AUTOSAR XML (schema 4-2-2)
package /STELLANTIS/EPT/ASWCs
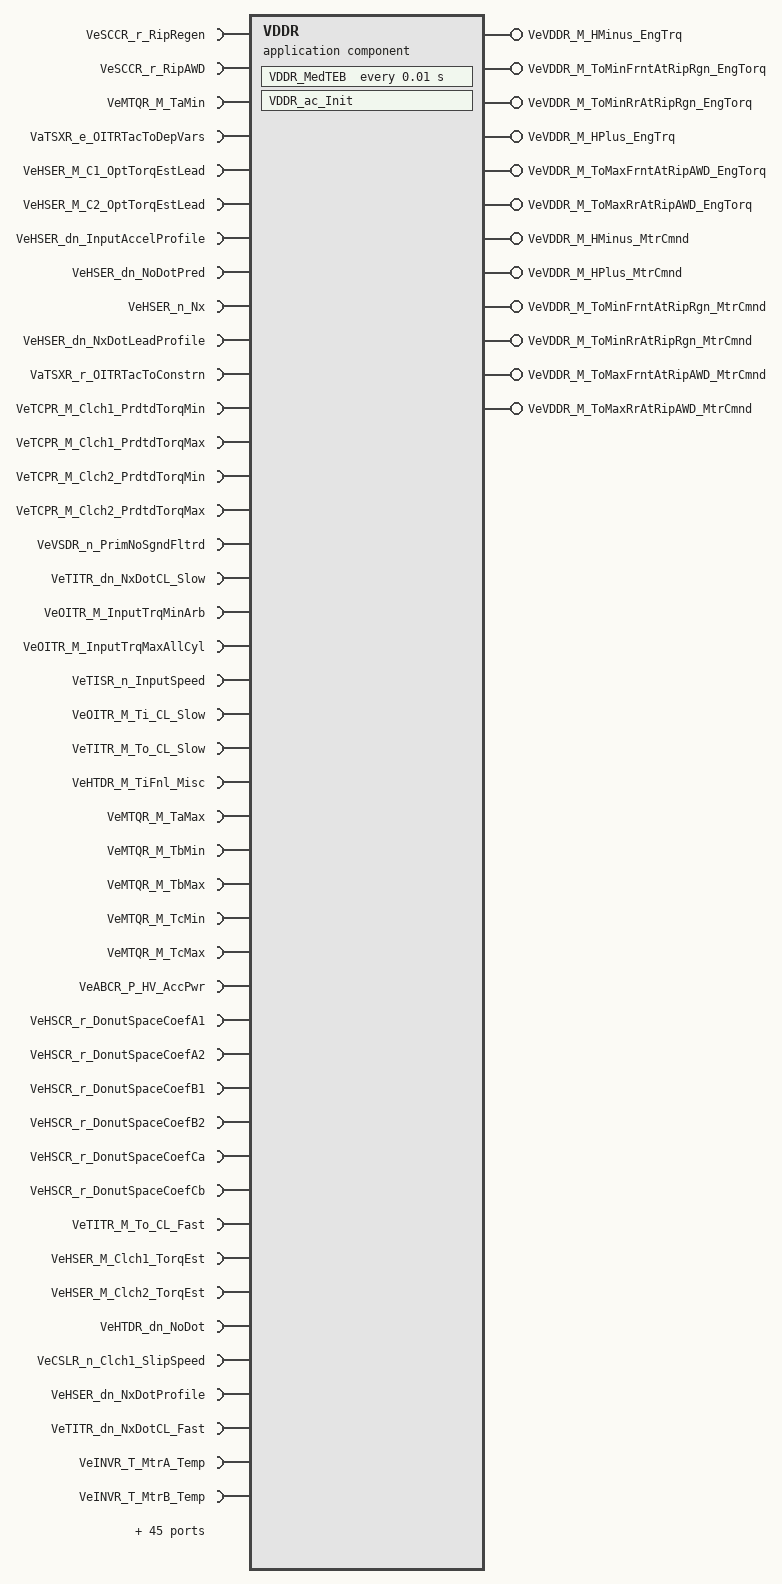
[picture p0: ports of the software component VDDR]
  application sw component type VDDR
    72 x require port:
      VeSCCR_r_RipRegen: variation-point={short-label=vpVeSCCR_r_RipRegen, sw-syscond=1}, nonqueued-receiver-com-spec{data-element=Value, init-value=0}, required-interface=VeSCCR_r_RipRegen
      VeSCCR_r_RipAWD: variation-point={short-label=vpVeSCCR_r_RipAWD, sw-syscond=1}, nonqueued-receiver-com-spec{data-element=Value, init-value=0}, required-interface=VeSCCR_r_RipAWD
      VeMTQR_M_TaMin: variation-point={short-label=vpVeMTQR_M_TaMin, sw-syscond=1}, nonqueued-receiver-com-spec{data-element=Value, init-value=0}, required-interface=VeMTQR_M_TaMin
      VaTSXR_e_OITRTacToDepVars: variation-point={short-label=vpVaTSXR_e_OITRTacToDepVars, sw-syscond=1}, nonqueued-receiver-com-spec{data-element=Value, init-value=6 x CeTSXR_e_Ta}, required-interface=VaTSXR_e_OITRTacToDepVars
      VeHSER_M_C1_OptTorqEstLead: variation-point={short-label=vpVeHSER_M_C1_OptTorqEstLead, sw-syscond=1}, nonqueued-receiver-com-spec{data-element=Value, init-value=0}, required-interface=VeHSER_M_C1_OptTorqEstLead
      VeHSER_M_C2_OptTorqEstLead: variation-point={short-label=vpVeHSER_M_C2_OptTorqEstLead, sw-syscond=1}, nonqueued-receiver-com-spec{data-element=Value, init-value=0}, required-interface=VeHSER_M_C2_OptTorqEstLead
      VeHSER_dn_InputAccelProfile: variation-point={short-label=vpVeHSER_dn_InputAccelProfile, sw-syscond=1}, nonqueued-receiver-com-spec{data-element=Value, init-value=0}, required-interface=VeHSER_dn_InputAccelProfile
      VeHSER_dn_NoDotPred: variation-point={short-label=vpVeHSER_dn_NoDotPred, sw-syscond=1}, nonqueued-receiver-com-spec{data-element=Value, init-value=0}, required-interface=VeHSER_dn_NoDotPred
      VeHSER_n_Nx: variation-point={short-label=vpVeHSER_n_Nx, sw-syscond=1}, nonqueued-receiver-com-spec{data-element=Value, init-value=0}, required-interface=VeHSER_n_Nx
      VeHSER_dn_NxDotLeadProfile: variation-point={short-label=vpVeHSER_dn_NxDotLeadProfile, sw-syscond=1}, nonqueued-receiver-com-spec{data-element=Value, init-value=0}, required-interface=VeHSER_dn_NxDotLeadProfile
      VaTSXR_r_OITRTacToConstrn: variation-point={short-label=vpVaTSXR_r_OITRTacToConstrn, sw-syscond=1}, nonqueued-receiver-com-spec{data-element=Value, init-value=114 x 0}, required-interface=VaTSXR_r_OITRTacToConstrn
      VeTCPR_M_Clch1_PrdtdTorqMin: variation-point={short-label=vpVeTCPR_M_Clch1_PrdtdTorqMin, sw-syscond=1}, nonqueued-receiver-com-spec{data-element=Value, init-value=0}, required-interface=VeTCPR_M_Clch1_PrdtdTorqMin
      VeTCPR_M_Clch1_PrdtdTorqMax: variation-point={short-label=vpVeTCPR_M_Clch1_PrdtdTorqMax, sw-syscond=1}, nonqueued-receiver-com-spec{data-element=Value, init-value=0}, required-interface=VeTCPR_M_Clch1_PrdtdTorqMax
      VeTCPR_M_Clch2_PrdtdTorqMin: variation-point={short-label=vpVeTCPR_M_Clch2_PrdtdTorqMin, sw-syscond=1}, nonqueued-receiver-com-spec{data-element=Value, init-value=0}, required-interface=VeTCPR_M_Clch2_PrdtdTorqMin
      VeTCPR_M_Clch2_PrdtdTorqMax: variation-point={short-label=vpVeTCPR_M_Clch2_PrdtdTorqMax, sw-syscond=1}, nonqueued-receiver-com-spec{data-element=Value, init-value=0}, required-interface=VeTCPR_M_Clch2_PrdtdTorqMax
      VeVSDR_n_PrimNoSgndFltrd: variation-point={short-label=vpVeVSDR_n_PrimNoSgndFltrd, sw-syscond=1}, nonqueued-receiver-com-spec{data-element=Value, init-value=0}, required-interface=VeVSDR_n_PrimNoSgndFltrd
      VeTITR_dn_NxDotCL_Slow: variation-point={short-label=vpVeTITR_dn_NxDotCL_Slow, sw-syscond=1}, nonqueued-receiver-com-spec{data-element=Value, init-value=0}, required-interface=VeTITR_dn_NxDotCL_Slow
      VeOITR_M_InputTrqMinArb: variation-point={short-label=vpVeOITR_M_InputTrqMinArb, sw-syscond=1}, nonqueued-receiver-com-spec{data-element=Value, init-value=0}, required-interface=VeOITR_M_InputTrqMinArb
      VeOITR_M_InputTrqMaxAllCyl: variation-point={short-label=vpVeOITR_M_InputTrqMaxAllCyl, sw-syscond=1}, nonqueued-receiver-com-spec{data-element=Value, init-value=0}, required-interface=VeOITR_M_InputTrqMaxAllCyl
      VeTISR_n_InputSpeed: variation-point={short-label=vpVeTISR_n_InputSpeed, sw-syscond=1}, nonqueued-receiver-com-spec{data-element=Value, init-value=0}, required-interface=VeTISR_n_InputSpeed
      VeOITR_M_Ti_CL_Slow: variation-point={short-label=vpVeOITR_M_Ti_CL_Slow, sw-syscond=1}, nonqueued-receiver-com-spec{data-element=Value, init-value=0}, required-interface=VeOITR_M_Ti_CL_Slow
      VeTITR_M_To_CL_Slow: variation-point={short-label=vpVeTITR_M_To_CL_Slow, sw-syscond=1}, nonqueued-receiver-com-spec{data-element=Value, init-value=0}, required-interface=VeTITR_M_To_CL_Slow
      VeHTDR_M_TiFnl_Misc: variation-point={short-label=vpVeHTDR_M_TiFnl_Misc, sw-syscond=1}, nonqueued-receiver-com-spec{data-element=Value, init-value=0}, required-interface=VeHTDR_M_TiFnl_Misc
      VeMTQR_M_TaMax: variation-point={short-label=vpVeMTQR_M_TaMax, sw-syscond=1}, nonqueued-receiver-com-spec{data-element=Value, init-value=0}, required-interface=VeMTQR_M_TaMax
      VeMTQR_M_TbMin: variation-point={short-label=vpVeMTQR_M_TbMin, sw-syscond=1}, nonqueued-receiver-com-spec{data-element=Value, init-value=0}, required-interface=VeMTQR_M_TbMin
      VeMTQR_M_TbMax: variation-point={short-label=vpVeMTQR_M_TbMax, sw-syscond=1}, nonqueued-receiver-com-spec{data-element=Value, init-value=0}, required-interface=VeMTQR_M_TbMax
      VeMTQR_M_TcMin: variation-point={short-label=vpVeMTQR_M_TcMin, sw-syscond=1}, nonqueued-receiver-com-spec{data-element=Value, init-value=0}, required-interface=VeMTQR_M_TcMin
      VeMTQR_M_TcMax: variation-point={short-label=vpVeMTQR_M_TcMax, sw-syscond=1}, nonqueued-receiver-com-spec{data-element=Value, init-value=0}, required-interface=VeMTQR_M_TcMax
      VeABCR_P_HV_AccPwr: variation-point={short-label=vpVeABCR_P_HV_AccPwr, sw-syscond=1}, nonqueued-receiver-com-spec{data-element=Value, init-value=0}, required-interface=VeABCR_P_HV_AccPwr
      VeHSCR_r_DonutSpaceCoefA1: variation-point={short-label=vpVeHSCR_r_DonutSpaceCoefA1, sw-syscond=1}, nonqueued-receiver-com-spec{data-element=Value, init-value=0}, required-interface=VeHSCR_r_DonutSpaceCoefA1
      VeHSCR_r_DonutSpaceCoefA2: variation-point={short-label=vpVeHSCR_r_DonutSpaceCoefA2, sw-syscond=1}, nonqueued-receiver-com-spec{data-element=Value, init-value=0}, required-interface=VeHSCR_r_DonutSpaceCoefA2
      VeHSCR_r_DonutSpaceCoefB1: variation-point={short-label=vpVeHSCR_r_DonutSpaceCoefB1, sw-syscond=1}, nonqueued-receiver-com-spec{data-element=Value, init-value=0}, required-interface=VeHSCR_r_DonutSpaceCoefB1
      VeHSCR_r_DonutSpaceCoefB2: variation-point={short-label=vpVeHSCR_r_DonutSpaceCoefB2, sw-syscond=1}, nonqueued-receiver-com-spec{data-element=Value, init-value=0}, required-interface=VeHSCR_r_DonutSpaceCoefB2
      VeHSCR_r_DonutSpaceCoefCa: variation-point={short-label=vpVeHSCR_r_DonutSpaceCoefCa, sw-syscond=1}, nonqueued-receiver-com-spec{data-element=Value, init-value=0}, required-interface=VeHSCR_r_DonutSpaceCoefCa
      VeHSCR_r_DonutSpaceCoefCb: variation-point={short-label=vpVeHSCR_r_DonutSpaceCoefCb, sw-syscond=1}, nonqueued-receiver-com-spec{data-element=Value, init-value=0}, required-interface=VeHSCR_r_DonutSpaceCoefCb
      VeTITR_M_To_CL_Fast: variation-point={short-label=vpVeTITR_M_To_CL_Fast, sw-syscond=1}, nonqueued-receiver-com-spec{data-element=Value, init-value=0}, required-interface=VeTITR_M_To_CL_Fast
      VeHSER_M_Clch1_TorqEst: variation-point={short-label=vpVeHSER_M_Clch1_TorqEst, sw-syscond=1}, nonqueued-receiver-com-spec{data-element=Value, init-value=0}, required-interface=VeHSER_M_Clch1_TorqEst
      VeHSER_M_Clch2_TorqEst: variation-point={short-label=vpVeHSER_M_Clch2_TorqEst, sw-syscond=1}, nonqueued-receiver-com-spec{data-element=Value, init-value=0}, required-interface=VeHSER_M_Clch2_TorqEst
      VeHTDR_dn_NoDot: variation-point={short-label=vpVeHTDR_dn_NoDot, sw-syscond=1}, nonqueued-receiver-com-spec{data-element=Value, init-value=0}, required-interface=VeHTDR_dn_NoDot
      VeCSLR_n_Clch1_SlipSpeed: variation-point={short-label=vpVeCSLR_n_Clch1_SlipSpeed, sw-syscond=1}, nonqueued-receiver-com-spec{data-element=Value, init-value=0}, required-interface=VeCSLR_n_Clch1_SlipSpeed
      VeHSER_dn_NxDotProfile: variation-point={short-label=vpVeHSER_dn_NxDotProfile, sw-syscond=1}, nonqueued-receiver-com-spec{data-element=Value, init-value=0}, required-interface=VeHSER_dn_NxDotProfile
      VeTITR_dn_NxDotCL_Fast: variation-point={short-label=vpVeTITR_dn_NxDotCL_Fast, sw-syscond=1}, nonqueued-receiver-com-spec{data-element=Value, init-value=0}, required-interface=VeTITR_dn_NxDotCL_Fast
      VeINVR_T_MtrA_Temp: variation-point={short-label=vpVeINVR_T_MtrA_Temp, sw-syscond=1}, nonqueued-receiver-com-spec{data-element=Value, init-value=0}, required-interface=VeINVR_T_MtrA_Temp
      VeINVR_T_MtrB_Temp: variation-point={short-label=vpVeINVR_T_MtrB_Temp, sw-syscond=1}, nonqueued-receiver-com-spec{data-element=Value, init-value=0}, required-interface=VeINVR_T_MtrB_Temp
      VeINVR_T_MtrC_Temp: variation-point={short-label=vpVeINVR_T_MtrC_Temp, sw-syscond=1}, nonqueued-receiver-com-spec{data-element=Value, init-value=0}, required-interface=VeINVR_T_MtrC_Temp
      VeINVR_T_MtrA_InvrtrTemp: variation-point={short-label=vpVeINVR_T_MtrA_InvrtrTemp, sw-syscond=1}, nonqueued-receiver-com-spec{data-element=Value, init-value=0}, required-interface=VeINVR_T_MtrA_InvrtrTemp
      VeINVR_T_MtrB_InvrtrTemp: variation-point={short-label=vpVeINVR_T_MtrB_InvrtrTemp, sw-syscond=1}, nonqueued-receiver-com-spec{data-element=Value, init-value=0}, required-interface=VeINVR_T_MtrB_InvrtrTemp
      VeINVR_T_MtrC_InvrtrTemp: variation-point={short-label=vpVeINVR_T_MtrC_InvrtrTemp, sw-syscond=1}, nonqueued-receiver-com-spec{data-element=Value, init-value=0}, required-interface=VeINVR_T_MtrC_InvrtrTemp
      VeCSLR_n_Clch{2..4}_SlipSpeed: variation-point={short-label=vpVeCSLR_n_Clch{2..4}_SlipSpeed, sw-syscond=1}, nonqueued-receiver-com-spec{data-element=Value, init-value=0}, required-interface=VeCSLR_n_Clch{2..4}_SlipSpeed
      VeTCPR_M_Clch1_TorqEstMin: variation-point={short-label=vpVeTCPR_M_Clch1_TorqEstMin, sw-syscond=1}, nonqueued-receiver-com-spec{data-element=Value, init-value=0}, required-interface=VeTCPR_M_Clch1_TorqEstMin
      VeTCPR_M_Clch1_TorqEstMax: variation-point={short-label=vpVeTCPR_M_Clch1_TorqEstMax, sw-syscond=1}, nonqueued-receiver-com-spec{data-element=Value, init-value=0}, required-interface=VeTCPR_M_Clch1_TorqEstMax
      VeTCPR_M_Clch2_TorqEstMin: variation-point={short-label=vpVeTCPR_M_Clch2_TorqEstMin, sw-syscond=1}, nonqueued-receiver-com-spec{data-element=Value, init-value=0}, required-interface=VeTCPR_M_Clch2_TorqEstMin
      VeTCPR_M_Clch2_TorqEstMax: variation-point={short-label=vpVeTCPR_M_Clch2_TorqEstMax, sw-syscond=1}, nonqueued-receiver-com-spec{data-element=Value, init-value=0}, required-interface=VeTCPR_M_Clch2_TorqEstMax
      VeMSPR_n_MtrA_Spd: variation-point={short-label=vpVeMSPR_n_MtrA_Spd, sw-syscond=1}, nonqueued-receiver-com-spec{data-element=Value, init-value=0}, required-interface=VeMSPR_n_MtrA_Spd
      VeTITR_M_TaCLSum: variation-point={short-label=vpVeTITR_M_TaCLSum, sw-syscond=1}, nonqueued-receiver-com-spec{data-element=Value, init-value=0}, required-interface=VeTITR_M_TaCLSum
      VeSCCR_M_FrntAxlCLMin: variation-point={short-label=vpVeSCCR_M_FrntAxlCLMin, sw-syscond=1}, nonqueued-receiver-com-spec{data-element=Value, init-value=0}, required-interface=VeSCCR_M_FrntAxlCLMin
      VeSCCR_M_FrntAxlCLMax: variation-point={short-label=vpVeSCCR_M_FrntAxlCLMax, sw-syscond=1}, nonqueued-receiver-com-spec{data-element=Value, init-value=0}, required-interface=VeSCCR_M_FrntAxlCLMax
      VeSCCR_M_RrAxlCLMin: variation-point={short-label=vpVeSCCR_M_RrAxlCLMin, sw-syscond=1}, nonqueued-receiver-com-spec{data-element=Value, init-value=0}, required-interface=VeSCCR_M_RrAxlCLMin
      VeSCCR_M_RrAxlCLMax: variation-point={short-label=vpVeSCCR_M_RrAxlCLMax, sw-syscond=1}, nonqueued-receiver-com-spec{data-element=Value, init-value=0}, required-interface=VeSCCR_M_RrAxlCLMax
      VaTSXR_r_HTDRToConstrn: variation-point={short-label=vpVaTSXR_r_HTDRToConstrn, sw-syscond=1}, nonqueued-receiver-com-spec{data-element=Value, init-value=114 x 0}, required-interface=VaTSXR_r_HTDRToConstrn
      VaTSXR_e_HTDRToDepVars: variation-point={short-label=vpVaTSXR_e_HTDRToDepVars, sw-syscond=1}, nonqueued-receiver-com-spec{data-element=Value, init-value=6 x CeTSXR_e_Ta}, required-interface=VaTSXR_e_HTDRToDepVars
      VaTSXR_b_HTDRToConstrnChk: variation-point={short-label=vpVaTSXR_b_HTDRToConstrnChk, sw-syscond=1}, nonqueued-receiver-com-spec{data-element=Value, init-value=6 x 0}, required-interface=VaTSXR_b_HTDRToConstrnChk
      VeTSXR_e_HTDRToConstrnType: variation-point={short-label=vpVeTSXR_e_HTDRToConstrnType, sw-syscond=1}, nonqueued-receiver-com-spec{data-element=Value, init-value=CeTSXR_e_Mode}, required-interface=VeTSXR_e_HTDRToConstrnType
      VeHTDR_P_PBatMax_OptTo: variation-point={short-label=vpVeHTDR_P_PBatMax_OptTo, sw-syscond=1}, nonqueued-receiver-com-spec{data-element=Value, init-value=0}, required-interface=VeHTDR_P_PBatMax_OptTo
      VeHTDR_P_PBatMin_OptTo: variation-point={short-label=vpVeHTDR_P_PBatMin_OptTo, sw-syscond=1}, nonqueued-receiver-com-spec{data-element=Value, init-value=0}, required-interface=VeHTDR_P_PBatMin_OptTo
      VeOITR_P_BatPwrMaxSysCnstrnt: variation-point={short-label=vpVeOITR_P_BatPwrMaxSysCnstrnt, sw-syscond=1}, nonqueued-receiver-com-spec{data-element=Value, init-value=0}, required-interface=VeOITR_P_BatPwrMaxSysCnstrnt
      VeOITR_P_BatPwrMinSysCnstrnt: variation-point={short-label=vpVeOITR_P_BatPwrMinSysCnstrnt, sw-syscond=1}, nonqueued-receiver-com-spec{data-element=Value, init-value=0}, required-interface=VeOITR_P_BatPwrMinSysCnstrnt
      VeOITR_dn_NiDot_SC: variation-point={short-label=vpVeOITR_dn_NiDot_SC, sw-syscond=1}, nonqueued-receiver-com-spec{data-element=Value, init-value=0}, required-interface=VeOITR_dn_NiDot_SC
      VeSCCR_M_FrntAxlMinRqPrtctd: variation-point={short-label=vpVeSCCR_M_FrntAxlMinRqPrtctd, sw-syscond=1}, nonqueued-receiver-com-spec{data-element=Value, init-value=0}, required-interface=VeSCCR_M_FrntAxlMinRqPrtctd
      VeSCCR_M_FrntAxlMaxRqPrtctd: variation-point={short-label=vpVeSCCR_M_FrntAxlMaxRqPrtctd, sw-syscond=1}, nonqueued-receiver-com-spec{data-element=Value, init-value=0}, required-interface=VeSCCR_M_FrntAxlMaxRqPrtctd
    12 x provide port, all with nonqueued-sender-com-spec{data-element=Value, init-value=0}:
      VeVDDR_M_HMinus_EngTrq: provided-interface=VeVDDR_M_HMinus_EngTrq
      VeVDDR_M_ToMinFrntAtRipRgn_EngTorq: provided-interface=VeVDDR_M_ToMinFrntAtRipRgn_EngTorq
      VeVDDR_M_ToMinRrAtRipRgn_EngTorq: provided-interface=VeVDDR_M_ToMinRrAtRipRgn_EngTorq
      VeVDDR_M_HPlus_EngTrq: provided-interface=VeVDDR_M_HPlus_EngTrq
      VeVDDR_M_ToMaxFrntAtRipAWD_EngTorq: provided-interface=VeVDDR_M_ToMaxFrntAtRipAWD_EngTorq
      VeVDDR_M_ToMaxRrAtRipAWD_EngTorq: provided-interface=VeVDDR_M_ToMaxRrAtRipAWD_EngTorq
      VeVDDR_M_HMinus_MtrCmnd: provided-interface=VeVDDR_M_HMinus_MtrCmnd
      VeVDDR_M_HPlus_MtrCmnd: provided-interface=VeVDDR_M_HPlus_MtrCmnd
      VeVDDR_M_ToMinFrntAtRipRgn_MtrCmnd: provided-interface=VeVDDR_M_ToMinFrntAtRipRgn_MtrCmnd
      VeVDDR_M_ToMinRrAtRipRgn_MtrCmnd: provided-interface=VeVDDR_M_ToMinRrAtRipRgn_MtrCmnd
      VeVDDR_M_ToMaxFrntAtRipAWD_MtrCmnd: provided-interface=VeVDDR_M_ToMaxFrntAtRipAWD_MtrCmnd
      VeVDDR_M_ToMaxRrAtRipAWD_MtrCmnd: provided-interface=VeVDDR_M_ToMaxRrAtRipAWD_MtrCmnd
    22 x require port:
      KeHSCR_K_Min_dist: parameter-require-com-spec{init-value=KeHSCR_K_Min_dist_KeHSCR_K_Min_dist:4.99999987368938E-05, parameter=KeHSCR_K_Min_dist}, required-interface=KeHSCR_K_Min_dist
      KeOPTR_Cf_Tc{1..4}GammaFact: parameter-require-com-spec{init-value=KeOPTR_Cf_Tc{1..4}GammaFact_KeOPTR_Cf_Tc{1..4}GammaFact:0.000104719758382998, parameter=KeOPTR_Cf_Tc{1..4}GammaFact}, required-interface=KeOPTR_Cf_Tc{1..4}GammaFact
      KeOPTR_M_ExtremeMaxTorque: parameter-require-com-spec{init-value=KeOPTR_M_ExtremeMaxTorque_KeOPTR_M_ExtremeMaxTorque:100000, parameter=KeOPTR_M_ExtremeMaxTorque}, required-interface=KeOPTR_M_ExtremeMaxTorque
      KeOPTR_M_ExtremeMinTorque: parameter-require-com-spec{init-value=KeOPTR_M_ExtremeMinTorque_KeOPTR_M_ExtremeMinTorque:-100000, parameter=KeOPTR_M_ExtremeMinTorque}, required-interface=KeOPTR_M_ExtremeMinTorque
      KeOPTR_k_NonZeroCoeffThrshld_Neg: parameter-require-com-spec{init-value=KeOPTR_k_NonZeroCoeffThrshld_Neg_KeOPTR_k_NonZeroCoeffThrshld_Neg:-9.99999974737875E-05, parameter=KeOPTR_k_NonZeroCoeffThrshld_Neg}, required-interface=KeOPTR_k_NonZeroCoeffThrshld_Neg
      KeOPTR_k_NonZeroCoeffThrshld_Pos: parameter-require-com-spec{init-value=KeOPTR_k_NonZeroCoeffThrshld_Pos_KeOPTR_k_NonZeroCoeffThrshld_Pos:9.99999974737875E-05, parameter=KeOPTR_k_NonZeroCoeffThrshld_Pos}, required-interface=KeOPTR_k_NonZeroCoeffThrshld_Pos
      HeOPTR_b_EnblSWALims: parameter-require-com-spec{init-value=HeOPTR_b_EnblSWALims_HeOPTR_b_EnblSWALims:0, parameter=HeOPTR_b_EnblSWALims}, required-interface=HeOPTR_b_EnblSWALims
      KtOPTR_r_TmpBsd_MtrA_OptToFctr: parameter-require-com-spec{init-value=[1 1 1 1 1 1], parameter=KtOPTR_r_TmpBsd_MtrA_OptToFctr}, required-interface=KtOPTR_r_TmpBsd_MtrA_OptToFctr
      KxOPTR_r_TmpBsd_MtrA_OptToFctr: parameter-require-com-spec{init-value=[90 150 175 195 200 250], parameter=KxOPTR_r_TmpBsd_MtrA_OptToFctr}, required-interface=KxOPTR_r_TmpBsd_MtrA_OptToFctr
      KtOPTR_r_TmpBsd_MtrB_OptToFctr: parameter-require-com-spec{init-value=[1 1 1 1 1 1], parameter=KtOPTR_r_TmpBsd_MtrB_OptToFctr}, required-interface=KtOPTR_r_TmpBsd_MtrB_OptToFctr
      KxOPTR_r_TmpBsd_MtrB_OptToFctr: parameter-require-com-spec{init-value=[90 150 175 195 200 250], parameter=KxOPTR_r_TmpBsd_MtrB_OptToFctr}, required-interface=KxOPTR_r_TmpBsd_MtrB_OptToFctr
      KtOPTR_r_TmpBsd_MtrC_OptToFctr: parameter-require-com-spec{init-value=[1 1 1 1 1 1], parameter=KtOPTR_r_TmpBsd_MtrC_OptToFctr}, required-interface=KtOPTR_r_TmpBsd_MtrC_OptToFctr
      KxOPTR_r_TmpBsd_MtrC_OptToFctr: parameter-require-com-spec{init-value=[90 150 175 195 200 250], parameter=KxOPTR_r_TmpBsd_MtrC_OptToFctr}, required-interface=KxOPTR_r_TmpBsd_MtrC_OptToFctr
      KtOPTR_r_TmpBsd_MtrInvrtrA_OptToFctr: parameter-require-com-spec{init-value=[1 1 1 1 1 1], parameter=KtOPTR_r_TmpBsd_MtrInvrtrA_OptToFctr}, required-interface=KtOPTR_r_TmpBsd_MtrInvrtrA_OptToFctr
      KxOPTR_r_TmpBsd_MtrInvrtrA_OptToFctr: parameter-require-com-spec{init-value=[30 35 40 45 49 50], parameter=KxOPTR_r_TmpBsd_MtrInvrtrA_OptToFctr}, required-interface=KxOPTR_r_TmpBsd_MtrInvrtrA_OptToFctr
      KtOPTR_r_TmpBsd_MtrInvrtrB_OptToFctr: parameter-require-com-spec{init-value=[1 1 1 1 1 1], parameter=KtOPTR_r_TmpBsd_MtrInvrtrB_OptToFctr}, required-interface=KtOPTR_r_TmpBsd_MtrInvrtrB_OptToFctr
      KxOPTR_r_TmpBsd_MtrInvrtrB_OptToFctr: parameter-require-com-spec{init-value=[30 35 40 45 49 50], parameter=KxOPTR_r_TmpBsd_MtrInvrtrB_OptToFctr}, required-interface=KxOPTR_r_TmpBsd_MtrInvrtrB_OptToFctr
      KtOPTR_r_TmpBsd_MtrInvrtrC_OptToFctr: parameter-require-com-spec{init-value=[1 1 1 1 1 1], parameter=KtOPTR_r_TmpBsd_MtrInvrtrC_OptToFctr}, required-interface=KtOPTR_r_TmpBsd_MtrInvrtrC_OptToFctr
      KxOPTR_r_TmpBsd_MtrInvrtrC_OptToFctr: parameter-require-com-spec{init-value=[30 35 40 45 49 50], parameter=KxOPTR_r_TmpBsd_MtrInvrtrC_OptToFctr}, required-interface=KxOPTR_r_TmpBsd_MtrInvrtrC_OptToFctr
    behavior IB_VDDR: data-type-mapping=msADTtoIDTMapping, handle-termination-and-restart=NO-SUPPORT, included-data-type-set=data-type=TeTSXR_e_PrfrdComb
      timing event Event_MedTEB: start-on-event=VDDR_MedTEB, period=0.01
      init event Event_VDDR_ac_Init: start-on-event=VDDR_ac_Init
      runnable VDDR_ac_Init
        data-send-points:
          12 x access:
            OUT_VeVDDR_M_HMinus_MtrCmnd_Value: accessed-variable=VeVDDR_M_HMinus_MtrCmnd.Value
            OUT_VeVDDR_M_ToMinFrntAtRipRgn_MtrCmnd_Value: accessed-variable=VeVDDR_M_ToMinFrntAtRipRgn_MtrCmnd.Value
            OUT_VeVDDR_M_ToMaxFrntAtRipAWD_EngTorq_Value: accessed-variable=VeVDDR_M_ToMaxFrntAtRipAWD_EngTorq.Value
            OUT_VeVDDR_M_ToMaxRrAtRipAWD_EngTorq_Value: accessed-variable=VeVDDR_M_ToMaxRrAtRipAWD_EngTorq.Value
            OUT_VeVDDR_M_ToMinRrAtRipRgn_MtrCmnd_Value: accessed-variable=VeVDDR_M_ToMinRrAtRipRgn_MtrCmnd.Value
            OUT_VeVDDR_M_ToMaxFrntAtRipAWD_MtrCmnd_Value: accessed-variable=VeVDDR_M_ToMaxFrntAtRipAWD_MtrCmnd.Value
            OUT_VeVDDR_M_ToMaxRrAtRipAWD_MtrCmnd_Value: accessed-variable=VeVDDR_M_ToMaxRrAtRipAWD_MtrCmnd.Value
            OUT_VeVDDR_M_HMinus_EngTrq_Value: accessed-variable=VeVDDR_M_HMinus_EngTrq.Value
            OUT_VeVDDR_M_HPlus_MtrCmnd_Value: accessed-variable=VeVDDR_M_HPlus_MtrCmnd.Value
            OUT_VeVDDR_M_HPlus_EngTrq_Value: accessed-variable=VeVDDR_M_HPlus_EngTrq.Value
            OUT_VeVDDR_M_ToMinFrntAtRipRgn_EngTorq_Value: accessed-variable=VeVDDR_M_ToMinFrntAtRipRgn_EngTorq.Value
            OUT_VeVDDR_M_ToMinRrAtRipRgn_EngTorq_Value: accessed-variable=VeVDDR_M_ToMinRrAtRipRgn_EngTorq.Value
      runnable VDDR_MedTEB
        data-receive-point-by-arguments:
          72 x access:
            IN_VaTSXR_b_HTDRToConstrnChk_Value: accessed-variable=VaTSXR_b_HTDRToConstrnChk.Value, variation-point={short-label=vpIN_VaTSXR_b_HTDRToConstrnChk_Value, sw-syscond=1}
            IN_VaTSXR_e_HTDRToDepVars_Value: accessed-variable=VaTSXR_e_HTDRToDepVars.Value, variation-point={short-label=vpIN_VaTSXR_e_HTDRToDepVars_Value, sw-syscond=1}
            IN_VaTSXR_e_OITRTacToDepVars_Value: accessed-variable=VaTSXR_e_OITRTacToDepVars.Value, variation-point={short-label=vpIN_VaTSXR_e_OITRTacToDepVars_Value, sw-syscond=1}
            IN_VaTSXR_r_HTDRToConstrn_Value: accessed-variable=VaTSXR_r_HTDRToConstrn.Value, variation-point={short-label=vpIN_VaTSXR_r_HTDRToConstrn_Value, sw-syscond=1}
            IN_VaTSXR_r_OITRTacToConstrn_Value: accessed-variable=VaTSXR_r_OITRTacToConstrn.Value, variation-point={short-label=vpIN_VaTSXR_r_OITRTacToConstrn_Value, sw-syscond=1}
            IN_VeABCR_P_HV_AccPwr_Value: accessed-variable=VeABCR_P_HV_AccPwr.Value, variation-point={short-label=vpIN_VeABCR_P_HV_AccPwr_Value, sw-syscond=1}
            IN_VeCSLR_n_Clch{1..4}_SlipSpeed_Value: accessed-variable=VeCSLR_n_Clch{1..4}_SlipSpeed.Value, variation-point={short-label=vpIN_VeCSLR_n_Clch{1..4}_SlipSpeed_Value, sw-syscond=1}
            IN_VeHSCR_r_DonutSpaceCoefA1_Value: accessed-variable=VeHSCR_r_DonutSpaceCoefA1.Value, variation-point={short-label=vpIN_VeHSCR_r_DonutSpaceCoefA1_Value, sw-syscond=1}
            IN_VeHSCR_r_DonutSpaceCoefA2_Value: accessed-variable=VeHSCR_r_DonutSpaceCoefA2.Value, variation-point={short-label=vpIN_VeHSCR_r_DonutSpaceCoefA2_Value, sw-syscond=1}
            IN_VeHSCR_r_DonutSpaceCoefB1_Value: accessed-variable=VeHSCR_r_DonutSpaceCoefB1.Value, variation-point={short-label=vpIN_VeHSCR_r_DonutSpaceCoefB1_Value, sw-syscond=1}
            IN_VeHSCR_r_DonutSpaceCoefB2_Value: accessed-variable=VeHSCR_r_DonutSpaceCoefB2.Value, variation-point={short-label=vpIN_VeHSCR_r_DonutSpaceCoefB2_Value, sw-syscond=1}
            IN_VeHSCR_r_DonutSpaceCoefCa_Value: accessed-variable=VeHSCR_r_DonutSpaceCoefCa.Value, variation-point={short-label=vpIN_VeHSCR_r_DonutSpaceCoefCa_Value, sw-syscond=1}
            IN_VeHSCR_r_DonutSpaceCoefCb_Value: accessed-variable=VeHSCR_r_DonutSpaceCoefCb.Value, variation-point={short-label=vpIN_VeHSCR_r_DonutSpaceCoefCb_Value, sw-syscond=1}
            IN_VeHSER_M_C1_OptTorqEstLead_Value: accessed-variable=VeHSER_M_C1_OptTorqEstLead.Value, variation-point={short-label=vpIN_VeHSER_M_C1_OptTorqEstLead_Value, sw-syscond=1}
            IN_VeHSER_M_C2_OptTorqEstLead_Value: accessed-variable=VeHSER_M_C2_OptTorqEstLead.Value, variation-point={short-label=vpIN_VeHSER_M_C2_OptTorqEstLead_Value, sw-syscond=1}
            IN_VeHSER_M_Clch1_TorqEst_Value: accessed-variable=VeHSER_M_Clch1_TorqEst.Value, variation-point={short-label=vpIN_VeHSER_M_Clch1_TorqEst_Value, sw-syscond=1}
            IN_VeHSER_M_Clch2_TorqEst_Value: accessed-variable=VeHSER_M_Clch2_TorqEst.Value, variation-point={short-label=vpIN_VeHSER_M_Clch2_TorqEst_Value, sw-syscond=1}
            IN_VeHSER_dn_InputAccelProfile_Value: accessed-variable=VeHSER_dn_InputAccelProfile.Value, variation-point={short-label=vpIN_VeHSER_dn_InputAccelProfile_Value, sw-syscond=1}
            IN_VeHSER_dn_NoDotPred_Value: accessed-variable=VeHSER_dn_NoDotPred.Value, variation-point={short-label=vpIN_VeHSER_dn_NoDotPred_Value, sw-syscond=1}
            IN_VeHSER_dn_NxDotLeadProfile_Value: accessed-variable=VeHSER_dn_NxDotLeadProfile.Value, variation-point={short-label=vpIN_VeHSER_dn_NxDotLeadProfile_Value, sw-syscond=1}
            IN_VeHSER_dn_NxDotProfile_Value: accessed-variable=VeHSER_dn_NxDotProfile.Value, variation-point={short-label=vpIN_VeHSER_dn_NxDotProfile_Value, sw-syscond=1}
            IN_VeHSER_n_Nx_Value: accessed-variable=VeHSER_n_Nx.Value, variation-point={short-label=vpIN_VeHSER_n_Nx_Value, sw-syscond=1}
            IN_VeHTDR_M_TiFnl_Misc_Value: accessed-variable=VeHTDR_M_TiFnl_Misc.Value, variation-point={short-label=vpIN_VeHTDR_M_TiFnl_Misc_Value, sw-syscond=1}
            IN_VeHTDR_P_PBatMax_OptTo_Value: accessed-variable=VeHTDR_P_PBatMax_OptTo.Value, variation-point={short-label=vpIN_VeHTDR_P_PBatMax_OptTo_Value, sw-syscond=1}
            IN_VeHTDR_P_PBatMin_OptTo_Value: accessed-variable=VeHTDR_P_PBatMin_OptTo.Value, variation-point={short-label=vpIN_VeHTDR_P_PBatMin_OptTo_Value, sw-syscond=1}
            IN_VeHTDR_dn_NoDot_Value: accessed-variable=VeHTDR_dn_NoDot.Value, variation-point={short-label=vpIN_VeHTDR_dn_NoDot_Value, sw-syscond=1}
            IN_VeINVR_T_MtrA_InvrtrTemp_Value: accessed-variable=VeINVR_T_MtrA_InvrtrTemp.Value, variation-point={short-label=vpIN_VeINVR_T_MtrA_InvrtrTemp_Value, sw-syscond=1}
            IN_VeINVR_T_MtrA_Temp_Value: accessed-variable=VeINVR_T_MtrA_Temp.Value, variation-point={short-label=vpIN_VeINVR_T_MtrA_Temp_Value, sw-syscond=1}
            IN_VeINVR_T_MtrB_InvrtrTemp_Value: accessed-variable=VeINVR_T_MtrB_InvrtrTemp.Value, variation-point={short-label=vpIN_VeINVR_T_MtrB_InvrtrTemp_Value, sw-syscond=1}
            IN_VeINVR_T_MtrB_Temp_Value: accessed-variable=VeINVR_T_MtrB_Temp.Value, variation-point={short-label=vpIN_VeINVR_T_MtrB_Temp_Value, sw-syscond=1}
            IN_VeINVR_T_MtrC_InvrtrTemp_Value: accessed-variable=VeINVR_T_MtrC_InvrtrTemp.Value, variation-point={short-label=vpIN_VeINVR_T_MtrC_InvrtrTemp_Value, sw-syscond=1}
            IN_VeINVR_T_MtrC_Temp_Value: accessed-variable=VeINVR_T_MtrC_Temp.Value, variation-point={short-label=vpIN_VeINVR_T_MtrC_Temp_Value, sw-syscond=1}
            IN_VeMSPR_n_MtrA_Spd_Value: accessed-variable=VeMSPR_n_MtrA_Spd.Value, variation-point={short-label=vpIN_VeMSPR_n_MtrA_Spd_Value, sw-syscond=1}
            IN_VeMTQR_M_TaMax_Value: accessed-variable=VeMTQR_M_TaMax.Value, variation-point={short-label=vpIN_VeMTQR_M_TaMax_Value, sw-syscond=1}
            IN_VeMTQR_M_TaMin_Value: accessed-variable=VeMTQR_M_TaMin.Value, variation-point={short-label=vpIN_VeMTQR_M_TaMin_Value, sw-syscond=1}
            IN_VeMTQR_M_TbMax_Value: accessed-variable=VeMTQR_M_TbMax.Value, variation-point={short-label=vpIN_VeMTQR_M_TbMax_Value, sw-syscond=1}
            IN_VeMTQR_M_TbMin_Value: accessed-variable=VeMTQR_M_TbMin.Value, variation-point={short-label=vpIN_VeMTQR_M_TbMin_Value, sw-syscond=1}
            IN_VeMTQR_M_TcMax_Value: accessed-variable=VeMTQR_M_TcMax.Value, variation-point={short-label=vpIN_VeMTQR_M_TcMax_Value, sw-syscond=1}
            IN_VeMTQR_M_TcMin_Value: accessed-variable=VeMTQR_M_TcMin.Value, variation-point={short-label=vpIN_VeMTQR_M_TcMin_Value, sw-syscond=1}
            IN_VeOITR_M_InputTrqMaxAllCyl_Value: accessed-variable=VeOITR_M_InputTrqMaxAllCyl.Value, variation-point={short-label=vpIN_VeOITR_M_InputTrqMaxAllCyl_Value, sw-syscond=1}
            IN_VeOITR_M_InputTrqMinArb_Value: accessed-variable=VeOITR_M_InputTrqMinArb.Value, variation-point={short-label=vpIN_VeOITR_M_InputTrqMinArb_Value, sw-syscond=1}
            IN_VeOITR_M_Ti_CL_Slow_Value: accessed-variable=VeOITR_M_Ti_CL_Slow.Value, variation-point={short-label=vpIN_VeOITR_M_Ti_CL_Slow_Value, sw-syscond=1}
            IN_VeOITR_P_BatPwrMaxSysCnstrnt_Value: accessed-variable=VeOITR_P_BatPwrMaxSysCnstrnt.Value, variation-point={short-label=vpIN_VeOITR_P_BatPwrMaxSysCnstrnt_Value, sw-syscond=1}
            IN_VeOITR_P_BatPwrMinSysCnstrnt_Value: accessed-variable=VeOITR_P_BatPwrMinSysCnstrnt.Value, variation-point={short-label=vpIN_VeOITR_P_BatPwrMinSysCnstrnt_Value, sw-syscond=1}
            IN_VeOITR_dn_NiDot_SC_Value: accessed-variable=VeOITR_dn_NiDot_SC.Value, variation-point={short-label=vpIN_VeOITR_dn_NiDot_SC_Value, sw-syscond=1}
            IN_VeSCCR_M_FrntAxlCLMax_Value: accessed-variable=VeSCCR_M_FrntAxlCLMax.Value, variation-point={short-label=vpIN_VeSCCR_M_FrntAxlCLMax_Value, sw-syscond=1}
            IN_VeSCCR_M_FrntAxlCLMin_Value: accessed-variable=VeSCCR_M_FrntAxlCLMin.Value, variation-point={short-label=vpIN_VeSCCR_M_FrntAxlCLMin_Value, sw-syscond=1}
            IN_VeSCCR_M_FrntAxlMaxRqPrtctd_Value: accessed-variable=VeSCCR_M_FrntAxlMaxRqPrtctd.Value, variation-point={short-label=vpIN_VeSCCR_M_FrntAxlMaxRqPrtctd_Value, sw-syscond=1}
            IN_VeSCCR_M_FrntAxlMinRqPrtctd_Value: accessed-variable=VeSCCR_M_FrntAxlMinRqPrtctd.Value, variation-point={short-label=vpIN_VeSCCR_M_FrntAxlMinRqPrtctd_Value, sw-syscond=1}
            IN_VeSCCR_M_RrAxlCLMax_Value: accessed-variable=VeSCCR_M_RrAxlCLMax.Value, variation-point={short-label=vpIN_VeSCCR_M_RrAxlCLMax_Value, sw-syscond=1}
            IN_VeSCCR_M_RrAxlCLMin_Value: accessed-variable=VeSCCR_M_RrAxlCLMin.Value, variation-point={short-label=vpIN_VeSCCR_M_RrAxlCLMin_Value, sw-syscond=1}
            IN_VeSCCR_r_RipAWD_Value: accessed-variable=VeSCCR_r_RipAWD.Value, variation-point={short-label=vpIN_VeSCCR_r_RipAWD_Value, sw-syscond=1}
            IN_VeSCCR_r_RipRegen_Value: accessed-variable=VeSCCR_r_RipRegen.Value, variation-point={short-label=vpIN_VeSCCR_r_RipRegen_Value, sw-syscond=1}
            IN_VeTCPR_M_Clch1_PrdtdTorqMax_Value: accessed-variable=VeTCPR_M_Clch1_PrdtdTorqMax.Value, variation-point={short-label=vpIN_VeTCPR_M_Clch1_PrdtdTorqMax_Value, sw-syscond=1}
            IN_VeTCPR_M_Clch1_PrdtdTorqMin_Value: accessed-variable=VeTCPR_M_Clch1_PrdtdTorqMin.Value, variation-point={short-label=vpIN_VeTCPR_M_Clch1_PrdtdTorqMin_Value, sw-syscond=1}
            IN_VeTCPR_M_Clch1_TorqEstMax_Value: accessed-variable=VeTCPR_M_Clch1_TorqEstMax.Value, variation-point={short-label=vpIN_VeTCPR_M_Clch1_TorqEstMax_Value, sw-syscond=1}
            IN_VeTCPR_M_Clch1_TorqEstMin_Value: accessed-variable=VeTCPR_M_Clch1_TorqEstMin.Value, variation-point={short-label=vpIN_VeTCPR_M_Clch1_TorqEstMin_Value, sw-syscond=1}
            IN_VeTCPR_M_Clch2_PrdtdTorqMax_Value: accessed-variable=VeTCPR_M_Clch2_PrdtdTorqMax.Value, variation-point={short-label=vpIN_VeTCPR_M_Clch2_PrdtdTorqMax_Value, sw-syscond=1}
            IN_VeTCPR_M_Clch2_PrdtdTorqMin_Value: accessed-variable=VeTCPR_M_Clch2_PrdtdTorqMin.Value, variation-point={short-label=vpIN_VeTCPR_M_Clch2_PrdtdTorqMin_Value, sw-syscond=1}
            IN_VeTCPR_M_Clch2_TorqEstMax_Value: accessed-variable=VeTCPR_M_Clch2_TorqEstMax.Value, variation-point={short-label=vpIN_VeTCPR_M_Clch2_TorqEstMax_Value, sw-syscond=1}
            IN_VeTCPR_M_Clch2_TorqEstMin_Value: accessed-variable=VeTCPR_M_Clch2_TorqEstMin.Value, variation-point={short-label=vpIN_VeTCPR_M_Clch2_TorqEstMin_Value, sw-syscond=1}
            IN_VeTISR_n_InputSpeed_Value: accessed-variable=VeTISR_n_InputSpeed.Value, variation-point={short-label=vpIN_VeTISR_n_InputSpeed_Value, sw-syscond=1}
            IN_VeTITR_M_TaCLSum_Value: accessed-variable=VeTITR_M_TaCLSum.Value, variation-point={short-label=vpIN_VeTITR_M_TaCLSum_Value, sw-syscond=1}
            IN_VeTITR_M_To_CL_Fast_Value: accessed-variable=VeTITR_M_To_CL_Fast.Value, variation-point={short-label=vpIN_VeTITR_M_To_CL_Fast_Value, sw-syscond=1}
            IN_VeTITR_M_To_CL_Slow_Value: accessed-variable=VeTITR_M_To_CL_Slow.Value, variation-point={short-label=vpIN_VeTITR_M_To_CL_Slow_Value, sw-syscond=1}
            IN_VeTITR_dn_NxDotCL_Fast_Value: accessed-variable=VeTITR_dn_NxDotCL_Fast.Value, variation-point={short-label=vpIN_VeTITR_dn_NxDotCL_Fast_Value, sw-syscond=1}
            IN_VeTITR_dn_NxDotCL_Slow_Value: accessed-variable=VeTITR_dn_NxDotCL_Slow.Value, variation-point={short-label=vpIN_VeTITR_dn_NxDotCL_Slow_Value, sw-syscond=1}
            IN_VeTSXR_e_HTDRToConstrnType_Value: accessed-variable=VeTSXR_e_HTDRToConstrnType.Value, variation-point={short-label=vpIN_VeTSXR_e_HTDRToConstrnType_Value, sw-syscond=1}
            IN_VeVSDR_n_PrimNoSgndFltrd_Value: accessed-variable=VeVSDR_n_PrimNoSgndFltrd.Value, variation-point={short-label=vpIN_VeVSDR_n_PrimNoSgndFltrd_Value, sw-syscond=1}
        data-send-points:
          12 x access:
            OUT_VeVDDR_M_HMinus_MtrCmnd_Value: accessed-variable=VeVDDR_M_HMinus_MtrCmnd.Value
            OUT_VeVDDR_M_HPlus_MtrCmnd_Value: accessed-variable=VeVDDR_M_HPlus_MtrCmnd.Value
            OUT_VeVDDR_M_ToMinFrntAtRipRgn_MtrCmnd_Value: accessed-variable=VeVDDR_M_ToMinFrntAtRipRgn_MtrCmnd.Value
            OUT_VeVDDR_M_ToMinRrAtRipRgn_MtrCmnd_Value: accessed-variable=VeVDDR_M_ToMinRrAtRipRgn_MtrCmnd.Value
            OUT_VeVDDR_M_ToMaxFrntAtRipAWD_MtrCmnd_Value: accessed-variable=VeVDDR_M_ToMaxFrntAtRipAWD_MtrCmnd.Value
            OUT_VeVDDR_M_ToMaxRrAtRipAWD_MtrCmnd_Value: accessed-variable=VeVDDR_M_ToMaxRrAtRipAWD_MtrCmnd.Value
            OUT_VeVDDR_M_HMinus_EngTrq_Value: accessed-variable=VeVDDR_M_HMinus_EngTrq.Value
            OUT_VeVDDR_M_HPlus_EngTrq_Value: accessed-variable=VeVDDR_M_HPlus_EngTrq.Value
            OUT_VeVDDR_M_ToMinFrntAtRipRgn_EngTorq_Value: accessed-variable=VeVDDR_M_ToMinFrntAtRipRgn_EngTorq.Value
            OUT_VeVDDR_M_ToMinRrAtRipRgn_EngTorq_Value: accessed-variable=VeVDDR_M_ToMinRrAtRipRgn_EngTorq.Value
            OUT_VeVDDR_M_ToMaxFrntAtRipAWD_EngTorq_Value: accessed-variable=VeVDDR_M_ToMaxFrntAtRipAWD_EngTorq.Value
            OUT_VeVDDR_M_ToMaxRrAtRipAWD_EngTorq_Value: accessed-variable=VeVDDR_M_ToMaxRrAtRipAWD_EngTorq.Value
        22 x parameter access:
          CALPRM_HeOPTR_b_EnblSWALims_HeOPTR_b_EnblSWALims: accessed-parameter=HeOPTR_b_EnblSWALims.HeOPTR_b_EnblSWALims, variation-point={short-label=vpCALPRM_HeOPTR_b_EnblSWALims_HeOPTR_b_EnblSWALims, sw-syscond=1}
          CALPRM_KeHSCR_K_Min_dist_KeHSCR_K_Min_dist: accessed-parameter=KeHSCR_K_Min_dist.KeHSCR_K_Min_dist, variation-point={short-label=vpCALPRM_KeHSCR_K_Min_dist_KeHSCR_K_Min_dist, sw-syscond=1}
          CALPRM_KeOPTR_Cf_Tc{1..4}GammaFact_KeOPTR_Cf_Tc{1..4}GammaFact: accessed-parameter=KeOPTR_Cf_Tc{1..4}GammaFact.KeOPTR_Cf_Tc{1..4}GammaFact, variation-point={short-label=vpCALPRM_KeOPTR_Cf_Tc{1..4}GammaFact_KeOPTR_Cf_Tc{1..4}GammaFact, sw-syscond=1}
          CALPRM_KeOPTR_M_ExtremeMaxTorque_KeOPTR_M_ExtremeMaxTorque: accessed-parameter=KeOPTR_M_ExtremeMaxTorque.KeOPTR_M_ExtremeMaxTorque, variation-point={short-label=vpCALPRM_KeOPTR_M_ExtremeMaxTorque_KeOPTR_M_ExtremeMaxTorque, sw-syscond=1}
          CALPRM_KeOPTR_M_ExtremeMinTorque_KeOPTR_M_ExtremeMinTorque: accessed-parameter=KeOPTR_M_ExtremeMinTorque.KeOPTR_M_ExtremeMinTorque, variation-point={short-label=vpCALPRM_KeOPTR_M_ExtremeMinTorque_KeOPTR_M_ExtremeMinTorque, sw-syscond=1}
          CALPRM_KeOPTR_k_NonZeroCoeffThrshld_Neg_KeOPTR_k_NonZeroCoeffThrshld_Neg: accessed-parameter=KeOPTR_k_NonZeroCoeffThrshld_Neg.KeOPTR_k_NonZeroCoeffThrshld_Neg, variation-point={short-label=vpCALPRM_KeOPTR_k_NonZeroCoeffThrshld_Neg_KeOPTR_k_NonZeroCoeffThrshld_Neg, sw-syscond=1}
          CALPRM_KeOPTR_k_NonZeroCoeffThrshld_Pos_KeOPTR_k_NonZeroCoeffThrshld_Pos: accessed-parameter=KeOPTR_k_NonZeroCoeffThrshld_Pos.KeOPTR_k_NonZeroCoeffThrshld_Pos, variation-point={short-label=vpCALPRM_KeOPTR_k_NonZeroCoeffThrshld_Pos_KeOPTR_k_NonZeroCoeffThrshld_Pos, sw-syscond=1}
          CALPRM_KtOPTR_r_TmpBsd_MtrA_OptToFctr_KtOPTR_r_TmpBsd_MtrA_OptToFctr: accessed-parameter=KtOPTR_r_TmpBsd_MtrA_OptToFctr.KtOPTR_r_TmpBsd_MtrA_OptToFctr, variation-point={short-label=vpCALPRM_KtOPTR_r_TmpBsd_MtrA_OptToFctr_KtOPTR_r_TmpBsd_MtrA_OptToFctr, sw-syscond=1}
          CALPRM_KtOPTR_r_TmpBsd_MtrB_OptToFctr_KtOPTR_r_TmpBsd_MtrB_OptToFctr: accessed-parameter=KtOPTR_r_TmpBsd_MtrB_OptToFctr.KtOPTR_r_TmpBsd_MtrB_OptToFctr, variation-point={short-label=vpCALPRM_KtOPTR_r_TmpBsd_MtrB_OptToFctr_KtOPTR_r_TmpBsd_MtrB_OptToFctr, sw-syscond=1}
          CALPRM_KtOPTR_r_TmpBsd_MtrC_OptToFctr_KtOPTR_r_TmpBsd_MtrC_OptToFctr: accessed-parameter=KtOPTR_r_TmpBsd_MtrC_OptToFctr.KtOPTR_r_TmpBsd_MtrC_OptToFctr, variation-point={short-label=vpCALPRM_KtOPTR_r_TmpBsd_MtrC_OptToFctr_KtOPTR_r_TmpBsd_MtrC_OptToFctr, sw-syscond=1}
          CALPRM_KtOPTR_r_TmpBsd_MtrInvrtrA_OptToFctr_KtOPTR_r_TmpBsd_MtrInvrtrA_OptToFctr: accessed-parameter=KtOPTR_r_TmpBsd_MtrInvrtrA_OptToFctr.KtOPTR_r_TmpBsd_MtrInvrtrA_OptToFctr, variation-point={short-label=vpCALPRM_KtOPTR_r_TmpBsd_MtrInvrtrA_OptToFctr_KtOPTR_r_TmpBsd_MtrInvrtrA_OptToFctr, sw-syscond=1}
          CALPRM_KtOPTR_r_TmpBsd_MtrInvrtrB_OptToFctr_KtOPTR_r_TmpBsd_MtrInvrtrB_OptToFctr: accessed-parameter=KtOPTR_r_TmpBsd_MtrInvrtrB_OptToFctr.KtOPTR_r_TmpBsd_MtrInvrtrB_OptToFctr, variation-point={short-label=vpCALPRM_KtOPTR_r_TmpBsd_MtrInvrtrB_OptToFctr_KtOPTR_r_TmpBsd_MtrInvrtrB_OptToFctr, sw-syscond=1}
          CALPRM_KtOPTR_r_TmpBsd_MtrInvrtrC_OptToFctr_KtOPTR_r_TmpBsd_MtrInvrtrC_OptToFctr: accessed-parameter=KtOPTR_r_TmpBsd_MtrInvrtrC_OptToFctr.KtOPTR_r_TmpBsd_MtrInvrtrC_OptToFctr, variation-point={short-label=vpCALPRM_KtOPTR_r_TmpBsd_MtrInvrtrC_OptToFctr_KtOPTR_r_TmpBsd_MtrInvrtrC_OptToFctr, sw-syscond=1}
          CALPRM_KxOPTR_r_TmpBsd_MtrA_OptToFctr_KxOPTR_r_TmpBsd_MtrA_OptToFctr: accessed-parameter=KxOPTR_r_TmpBsd_MtrA_OptToFctr.KxOPTR_r_TmpBsd_MtrA_OptToFctr, variation-point={short-label=vpCALPRM_KxOPTR_r_TmpBsd_MtrA_OptToFctr_KxOPTR_r_TmpBsd_MtrA_OptToFctr, sw-syscond=1}
          CALPRM_KxOPTR_r_TmpBsd_MtrB_OptToFctr_KxOPTR_r_TmpBsd_MtrB_OptToFctr: accessed-parameter=KxOPTR_r_TmpBsd_MtrB_OptToFctr.KxOPTR_r_TmpBsd_MtrB_OptToFctr, variation-point={short-label=vpCALPRM_KxOPTR_r_TmpBsd_MtrB_OptToFctr_KxOPTR_r_TmpBsd_MtrB_OptToFctr, sw-syscond=1}
          CALPRM_KxOPTR_r_TmpBsd_MtrC_OptToFctr_KxOPTR_r_TmpBsd_MtrC_OptToFctr: accessed-parameter=KxOPTR_r_TmpBsd_MtrC_OptToFctr.KxOPTR_r_TmpBsd_MtrC_OptToFctr, variation-point={short-label=vpCALPRM_KxOPTR_r_TmpBsd_MtrC_OptToFctr_KxOPTR_r_TmpBsd_MtrC_OptToFctr, sw-syscond=1}
          CALPRM_KxOPTR_r_TmpBsd_MtrInvrtrA_OptToFctr_KxOPTR_r_TmpBsd_MtrInvrtrA_OptToFctr: accessed-parameter=KxOPTR_r_TmpBsd_MtrInvrtrA_OptToFctr.KxOPTR_r_TmpBsd_MtrInvrtrA_OptToFctr, variation-point={short-label=vpCALPRM_KxOPTR_r_TmpBsd_MtrInvrtrA_OptToFctr_KxOPTR_r_TmpBsd_MtrInvrtrA_OptToFctr, sw-syscond=1}
          CALPRM_KxOPTR_r_TmpBsd_MtrInvrtrB_OptToFctr_KxOPTR_r_TmpBsd_MtrInvrtrB_OptToFctr: accessed-parameter=KxOPTR_r_TmpBsd_MtrInvrtrB_OptToFctr.KxOPTR_r_TmpBsd_MtrInvrtrB_OptToFctr, variation-point={short-label=vpCALPRM_KxOPTR_r_TmpBsd_MtrInvrtrB_OptToFctr_KxOPTR_r_TmpBsd_MtrInvrtrB_OptToFctr, sw-syscond=1}
          CALPRM_KxOPTR_r_TmpBsd_MtrInvrtrC_OptToFctr_KxOPTR_r_TmpBsd_MtrInvrtrC_OptToFctr: accessed-parameter=KxOPTR_r_TmpBsd_MtrInvrtrC_OptToFctr.KxOPTR_r_TmpBsd_MtrInvrtrC_OptToFctr, variation-point={short-label=vpCALPRM_KxOPTR_r_TmpBsd_MtrInvrtrC_OptToFctr_KxOPTR_r_TmpBsd_MtrInvrtrC_OptToFctr, sw-syscond=1}
      4 x variation point proxy, all with category=CONDITION:
        Variant_HSCL_3Mot_Enbl: condition-access=0
        Variant_OPTL_3MtrEnbl: condition-access=0
        Variant_VDDR_1: condition-access=1
        Variant_VDDR_3: condition-access=0
